VERSION ""

NS_ :

BS_:

BU_: Lenkmotor Third_Party VCU

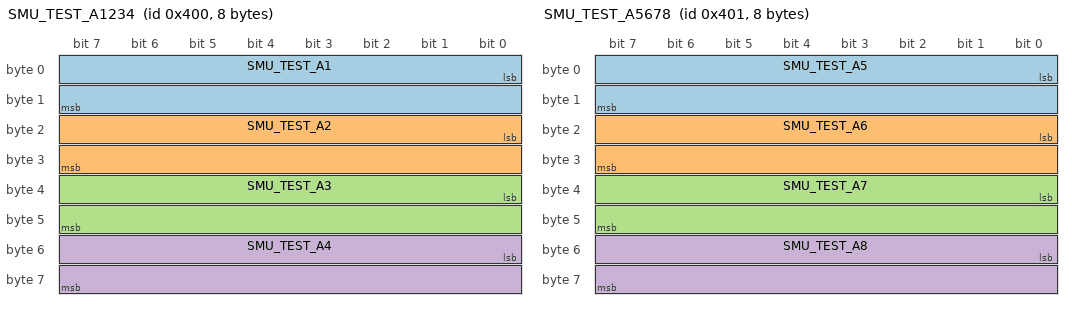
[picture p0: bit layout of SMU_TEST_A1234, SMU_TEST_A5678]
BO_ 1024 SMU_TEST_A1234: 8 Third_Party
 SG_ SMU_TEST_A1  : 0|16@1+ (0.001,0) [0|65.535] "V" Vector__XXX
 SG_ SMU_TEST_A2  : 16|16@1+ (0.001,0) [0|65.535] "V" Vector__XXX
 SG_ SMU_TEST_A3  : 32|16@1+ (0.001,0) [0|65.535] "V" Vector__XXX
 SG_ SMU_TEST_A4  : 48|16@1+ (0.001,0) [0|65.535] "V" Vector__XXX

BO_ 1025 SMU_TEST_A5678: 8 Third_Party
 SG_ SMU_TEST_A5  : 0|16@1+ (0.001,0) [0|65.535] "V" Vector__XXX
 SG_ SMU_TEST_A6  : 16|16@1+ (0.001,0) [0|65.535] "V" Vector__XXX
 SG_ SMU_TEST_A7  : 32|16@1+ (0.001,0) [0|65.535] "V" Vector__XXX
 SG_ SMU_TEST_A8  : 48|16@1+ (0.001,0) [0|65.535] "V" Vector__XXX

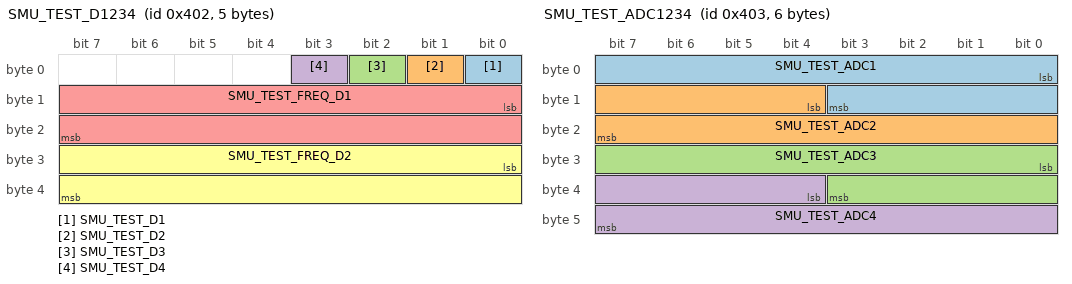
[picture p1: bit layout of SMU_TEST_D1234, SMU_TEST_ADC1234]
BO_ 1026 SMU_TEST_D1234: 5 Third_Party
 SG_ SMU_TEST_D1  : 0|1@1+ (1,0) [0|1] "" Vector__XXX
 SG_ SMU_TEST_D2  : 1|1@1+ (1,0) [0|1] "" Vector__XXX
 SG_ SMU_TEST_D3  : 2|1@1+ (1,0) [0|1] "" Vector__XXX
 SG_ SMU_TEST_D4  : 3|1@1+ (1,0) [0|1] "" Vector__XXX
 SG_ SMU_TEST_FREQ_D1  : 8|16@1+ (1,0) [0|65535] "Hz" Vector__XXX
 SG_ SMU_TEST_FREQ_D2  : 24|16@1+ (1,0) [0|65535] "Hz" Vector__XXX

BO_ 1027 SMU_TEST_ADC1234: 6 Third_Party
 SG_ SMU_TEST_ADC1  : 0|12@1+ (1,0) [0|4095] "" Vector__XXX
 SG_ SMU_TEST_ADC2  : 12|12@1+ (1,0) [0|4095] "" Vector__XXX
 SG_ SMU_TEST_ADC3  : 24|12@1+ (1,0) [0|4095] "" Vector__XXX
 SG_ SMU_TEST_ADC4  : 36|12@1+ (1,0) [0|4095] "" Vector__XXX

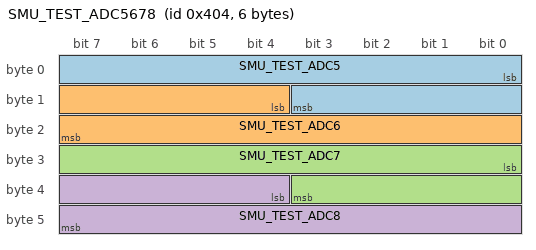
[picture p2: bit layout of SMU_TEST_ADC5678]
BO_ 1028 SMU_TEST_ADC5678: 6 Third_Party
 SG_ SMU_TEST_ADC5  : 0|12@1+ (1,0) [0|4095] "" Vector__XXX
 SG_ SMU_TEST_ADC6  : 12|12@1+ (1,0) [0|4095] "" Vector__XXX
 SG_ SMU_TEST_ADC7  : 24|12@1+ (1,0) [0|4095] "" Vector__XXX
 SG_ SMU_TEST_ADC8  : 36|12@1+ (1,0) [0|4095] "" Vector__XXX

BO_ 1664 CAN_Flash_RX: 8 Third_Party

BO_ 1679 CAN_Flash_SMU_test: 8 Third_Party

BA_DEF_  "DBName" STRING ;
BA_DEF_ BO_  "GenMsgSendType" ENUM  "Cyclic","OnEvent";
BA_DEF_ SG_  "GenSigSendType" ENUM  "NoSigSendType";
BA_DEF_ SG_  "GenSigStartValue" INT 0 0;
BA_DEF_ SG_  "SPN" INT 0 524287;
BA_DEF_DEF_  "DBName" "";
BA_DEF_DEF_  "GenMsgSendType" "NoMsgSendType";
BA_DEF_DEF_  "GenSigSendType" "Cyclic";
BA_DEF_DEF_  "SPN" 0;
BA_ "DBName" "CAN1";
BA_ "GenMsgSendType" BO_ 1024 1;
BA_ "GenMsgSendType" BO_ 1025 1;
BA_ "GenMsgSendType" BO_ 1026 1;
BA_ "GenMsgSendType" BO_ 1027 1;
BA_ "GenMsgSendType" BO_ 1028 1;
BA_ "GenMsgSendType" BO_ 1664 1;
BA_ "GenMsgSendType" BO_ 1679 1;
BA_ "GenSigStartValue" SG_ 1024 SMU_TEST_A1 0;
BA_ "GenSigStartValue" SG_ 1024 SMU_TEST_A2 0;
BA_ "GenSigStartValue" SG_ 1024 SMU_TEST_A3 0;
BA_ "GenSigStartValue" SG_ 1024 SMU_TEST_A4 0;
BA_ "GenSigStartValue" SG_ 1025 SMU_TEST_A5 0;
BA_ "GenSigStartValue" SG_ 1025 SMU_TEST_A6 0;
BA_ "GenSigStartValue" SG_ 1025 SMU_TEST_A7 0;
BA_ "GenSigStartValue" SG_ 1025 SMU_TEST_A8 0;
BA_ "GenSigStartValue" SG_ 1026 SMU_TEST_D1 0;
BA_ "GenSigStartValue" SG_ 1026 SMU_TEST_D2 0;
BA_ "GenSigStartValue" SG_ 1026 SMU_TEST_D3 0;
BA_ "GenSigStartValue" SG_ 1026 SMU_TEST_D4 0;
BA_ "GenSigStartValue" SG_ 1026 SMU_TEST_FREQ_D1 0;
BA_ "GenSigStartValue" SG_ 1026 SMU_TEST_FREQ_D2 0;
BA_ "GenSigStartValue" SG_ 1027 SMU_TEST_ADC1 0;
BA_ "GenSigStartValue" SG_ 1027 SMU_TEST_ADC2 0;
BA_ "GenSigStartValue" SG_ 1027 SMU_TEST_ADC3 0;
BA_ "GenSigStartValue" SG_ 1027 SMU_TEST_ADC4 0;
BA_ "GenSigStartValue" SG_ 1028 SMU_TEST_ADC5 0;
BA_ "GenSigStartValue" SG_ 1028 SMU_TEST_ADC6 0;
BA_ "GenSigStartValue" SG_ 1028 SMU_TEST_ADC7 0;
BA_ "GenSigStartValue" SG_ 1028 SMU_TEST_ADC8 0;
SIG_VALTYPE_ 1024 SMU_TEST_A1 : 0;
SIG_VALTYPE_ 1024 SMU_TEST_A2 : 0;
SIG_VALTYPE_ 1024 SMU_TEST_A3 : 0;
SIG_VALTYPE_ 1024 SMU_TEST_A4 : 0;
SIG_VALTYPE_ 1025 SMU_TEST_A5 : 0;
SIG_VALTYPE_ 1025 SMU_TEST_A6 : 0;
SIG_VALTYPE_ 1025 SMU_TEST_A7 : 0;
SIG_VALTYPE_ 1025 SMU_TEST_A8 : 0;
SIG_VALTYPE_ 1026 SMU_TEST_D1 : 0;
SIG_VALTYPE_ 1026 SMU_TEST_D2 : 0;
SIG_VALTYPE_ 1026 SMU_TEST_D3 : 0;
SIG_VALTYPE_ 1026 SMU_TEST_D4 : 0;
SIG_VALTYPE_ 1026 SMU_TEST_FREQ_D1 : 0;
SIG_VALTYPE_ 1026 SMU_TEST_FREQ_D2 : 0;
SIG_VALTYPE_ 1027 SMU_TEST_ADC1 : 0;
SIG_VALTYPE_ 1027 SMU_TEST_ADC2 : 0;
SIG_VALTYPE_ 1027 SMU_TEST_ADC3 : 0;
SIG_VALTYPE_ 1027 SMU_TEST_ADC4 : 0;
SIG_VALTYPE_ 1028 SMU_TEST_ADC5 : 0;
SIG_VALTYPE_ 1028 SMU_TEST_ADC6 : 0;
SIG_VALTYPE_ 1028 SMU_TEST_ADC7 : 0;
SIG_VALTYPE_ 1028 SMU_TEST_ADC8 : 0;
